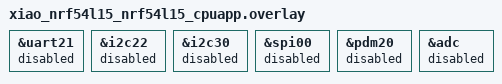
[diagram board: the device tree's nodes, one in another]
/*
 * Copyright (c) 2026
 *
 * SPDX-License-Identifier: LicenseRef-Nordic-5-Clause
 */

&uart21 {
	status = "disabled";
};

&i2c22 {
	status = "disabled";
};

&i2c30 {
	status = "disabled";
};

&spi00 {
	status = "disabled";
};

&pdm20 {
	status = "disabled";
};

&adc {
	status = "disabled";
};
